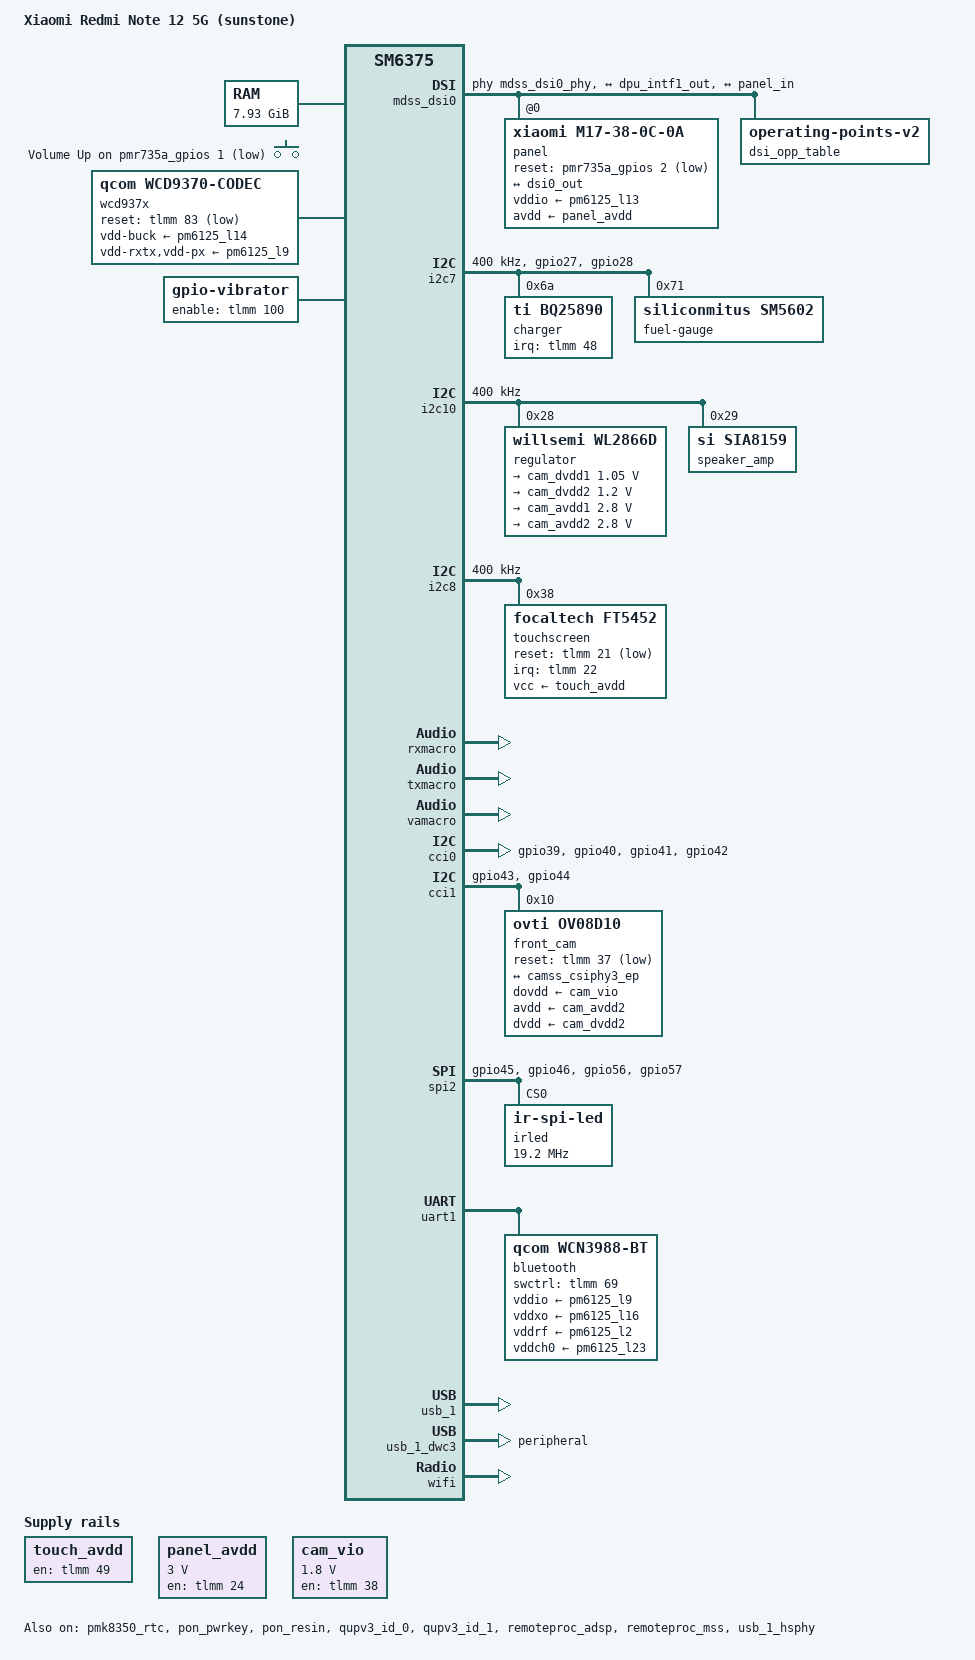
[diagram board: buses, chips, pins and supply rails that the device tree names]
// SPDX-License-Identifier: BSD-3-Clause
/*
 * Xiaomi Redmi Note 12 5G (sunstone), SM4375 "blair".
 *
 * Built on mainline's sm6375.dtsi ("holi", the SoC blair derives from: same CPU, GIC, GCC clock/reset
 * indices and USB block as the downstream blair DT). Board values from the phone's live DT
 * (2026-10-20) and the downstream DT. Until 2026-10-25 this was a chain of one tree per milestone
 * (m1 -> ... -> m6 -> m6d, each including the previous one); git tag dts-milestones has them.
 *
 * - USB: HS PHY on RPM regulators, dwc3 as a peripheral (the NCM gadget carries ssh).
 * - UFS: ufshc@4804000 with one lane and a QMP v4 PHY that downstream drives as
 *   "qcom,ufs-phy-qmp-v4-yupik" (SC7280 tables, kernel/patches/0001 adds the one-lane sm6375
 *   entry). Inline crypto (ICE) is left out. No interconnect driver for sm6375 yet: bus votes stay
 *   as ABL left them.
 * - PMICs as on the downstream DT and Sony's pdx225: PM6125 (SID 0/1), PMK8350 on SID 6, PMR735A.
 *   Keys (downstream gpio-keys and qpnp-power-on): power = PM6125 PON KPDPWR, volume down = PM6125
 *   PON RESIN, volume up = PMR735A GPIO1 (active low) -- the reverse of pdx225's volume keys.
 *   RTC: PMK8350 (read-only for Linux; the offset to real time is kept in userspace).
 * - Touch: FocalTech FT5452 at 0x38 on i2c8 (QUP1 SE2, GPIO19/20). TZ leaves that SE in GSI mode
 *   (FIFO disabled), which i2c-qcom-geni handles through GPI DMA. Reset GPIO21, IRQ GPIO22, AVDD
 *   switched by GPIO49 (downstream focaltech,avdd-gpio); the IO supply stays as ABL set it.
 * - Battery: on i2c7 (QUP1 SE1, GPIO27/28, FIFO mode), the SC8989X charger at 0x6a (BQ25890
 *   register map; IRQ GPIO48, charge enable GPIO53 low) and the SM5602 gauge at 0x71 (local patch
 *   0003).
 * - Modem (MPSS PAS) running the WLAN firmware of the WCN3988 (chip 0x150, WLAN.HL.3.3.2), which
 *   Linux talks to through ath10k snoc. Firmware comes read-only from the phone's modem_a partition
 *   (sunstone-fw-install in rootfs-overlay); rmtfs serves copies of modemst1/2, fsg and fsc, so the
 *   EFS partitions are never written. WLAN supplies as on the downstream icnss node (and Sony's
 *   pdx225): cx-mx PMR735A L2, 1.8 V XO PM6125 L16, 1.3 V RFA PM6125 L2, 3.3 V ch0/ch1 PM6125
 *   L23/L21. MSA at wlan@86500000 and the modem carveout at 0x8b800000 match the dtsi.
 * - GPU: sm6375.dtsi has no GPU nodes. This is mainline's a619_holi (chip id 0x06010901, GMU
 *   wrapper as on sm6115's a610), with values from the downstream kgsl node: registers 0x5900000 /
 *   cx 0x599e000 / dbgc 0x5961000, GMU wrapper 0x596a000, IRQ SPI 177, GX rail = RPM pm6125_s8
 *   levels (rpmpd VDDGX). Speed bins from the qfprom fuse at 0x6015 (downstream gpu_speed_bin):
 *   bins 0 and 190 run up to 900 MHz, 177 up to 840 MHz, 148 (this phone) up to 700 MHz; 650 MHz
 *   and below are common to all. The zap shader is the phone's own a615_zap (vendor partition, not
 *   in this repository).
 * - Display: MDSS/DPU/DSI laid out as mainline's qcom,sm6375-mdss binding example, with the
 *   downstream DT's values: MDSS IRQ SPI 186 (the binding example's 83 is not this SoC's), apps
 *   SMMU stream 0x820, DSC_0, INTF_1 to DSI0 + the 7nm PHY. The panel is the "m17 38 0c 0a"
 *   1080x2400 AMOLED in video mode with DSC 1.1 (kernel/patches/0008): vddio = PM6125 L13 1.86 V,
 *   avdd = 3.0 V switched by GPIO24, reset on PMR735A GPIO2 (active low), TE on GPIO23. DSI: vdda
 *   1.2 V = PM6125 L4, refgen. One msm DRM device drives display and GPU. ABL's splash is described
 *   as a simple-framebuffer, so simpledrm shows the console until msm's KMS takes over.
 * - Cameras: CCI0/CCI1 and CAMSS (TFE530/CSID530 as qcm2290's, CSIPHY 1.2.1; kernel/patches/0018)
 *   with the downstream DT's values. The sensors' cores and analog parts are on a WL2866D (i2c10,
 *   kernel/patches/0017), their I/O on GPIO38. Fitted: OV48B2Q main (cci0, no driver yet), SC202CS
 *   2 MP (cci1 0x36, no driver yet), OV08D10 front (cci1 0x10, CSIPHY3: described below).
 *
 * clk_ignore_unused and pd_ignore_unused (bootargs) keep GCC/RPM from switching off what ABL left
 * running.
 */
/dts-v1/;

#define PMK8350_SID 6

#include <dt-bindings/clock/qcom,sm6375-dispcc.h>
#include <dt-bindings/clock/qcom,sm6375-gpucc.h>
#include <dt-bindings/gpio/gpio.h>
#include <dt-bindings/soc/qcom,apr.h>
#include <dt-bindings/sound/qcom,q6afe.h>
#include <dt-bindings/sound/qcom,q6asm.h>
#include <dt-bindings/thermal/thermal.h>
#include "sm6375.dtsi"
#include "pm6125.dtsi"
#include "pmk8350.dtsi"
#include "pmr735a.dtsi"

/* the PM6125 PON is the one in use (downstream disables PMK8350's), and the labels collide */
/delete-node/ &pmk8350_pon;

/ {
	model = "Xiaomi Redmi Note 12 5G (sunstone)";
	compatible = "xiaomi,sunstone", "qcom,sm4375", "qcom,sm6375";
	chassis-type = "handset";

	aliases {
		/* the GENI UART driver takes its port number from here (Bluetooth; the console is tty0) */
		serial0 = &uart1;
	};

	chosen {
		#address-cells = <2>;
		#size-cells = <2>;
		ranges;
		/*
		 * consoleblank: the text console turns the panel off after 120 s (the phone is a server,
		 * screen off). watchdog.open_timeout: see the watchdog node.
		 */
		bootargs = "console=tty0 ignore_loglevel printk.devkmsg=on panic=20 reboot=warm rdinit=/init clk_ignore_unused pd_ignore_unused consoleblank=120 watchdog.open_timeout=120";

		framebuffer@85200000 {
			compatible = "simple-framebuffer";
			reg = <0x0 0x85200000 0x0 0xc00000>;
			width = <1080>;
			height = <2400>;
			stride = <(1080 * 4)>;
			format = "a8r8g8b8";
			memory-region = <&splash_mem>;
		};
	};

	memory@80000000 {
		reg = <0x0 0x80000000 0x0 0x3bb00000>,
		      <0x0 0xc0000000 0x0 0xc0000000>,
		      <0x1 0x80000000 0x1 0x00000000>;
	};

	reserved-memory {
		splash_mem: splash@85200000 {
			reg = <0x0 0x85200000 0x0 0xc00000>;
			no-map;
		};

		/* the downstream kernel's layout, so either kernel reads the other's records */
		ramoops@d0000000 {
			compatible = "ramoops";
			reg = <0x0 0xd0000000 0x0 0x200000>;
			console-size = <0x100000>;
			pmsg-size = <0x100000>;
		};
	};

	/* the touch controller's analog supply, switched by GPIO49; on already when ABL hands over */
	touch_avdd: touch-avdd-regulator {
		compatible = "regulator-fixed";
		regulator-name = "touch_avdd";
		gpio = <&tlmm 49 GPIO_ACTIVE_HIGH>;
		enable-active-high;
		regulator-boot-on;
		pinctrl-0 = <&ts_avdd_default>;
		pinctrl-names = "default";
	};

	panel_avdd: panel-avdd-regulator {
		compatible = "regulator-fixed";
		regulator-name = "panel_avdd";
		regulator-min-microvolt = <3000000>;
		regulator-max-microvolt = <3000000>;
		gpio = <&tlmm 24 GPIO_ACTIVE_HIGH>;
		enable-active-high;
		startup-delay-us = <233>;
		/* on when ABL hands over: the splash is showing */
		regulator-boot-on;
		pinctrl-0 = <&panel_avdd_default>;
		pinctrl-names = "default";
	};

	/*
	 * the camera modules' 1.8 V I/O supply, switched by GPIO38 (downstream CAM_VIO, shared by all
	 * sensors through cam-res-mgr); their cores and analog parts are on the WL2866D (i2c10)
	 */
	cam_vio: cam-vio-regulator {
		compatible = "regulator-fixed";
		regulator-name = "cam_vio";
		regulator-min-microvolt = <1800000>;
		regulator-max-microvolt = <1800000>;
		gpio = <&tlmm 38 GPIO_ACTIVE_HIGH>;
		enable-active-high;
		startup-delay-us = <1000>;
		pinctrl-0 = <&cam_vio_default>;
		pinctrl-names = "default";
	};

	gpio-keys {
		compatible = "gpio-keys";
		label = "gpio-keys";
		pinctrl-0 = <&vol_up_n>;
		pinctrl-names = "default";

		key-volume-up {
			label = "Volume Up";
			linux,code = <KEY_VOLUMEUP>;
			gpios = <&pmr735a_gpios 1 GPIO_ACTIVE_LOW>;
			debounce-interval = <15>;
			linux,can-disable;
			wakeup-source;
		};
	};

	/*
	 * Vibration motor: an enable on GPIO100. The downstream qcom,qpnp-vibrator-ldo-v2 node has no
	 * register, only the pin states vib_ldo_active (pull-up) and vib_ldo_suspend (pull-down); here
	 * the pin is driven instead.
	 */
	/*
	 * Audio codec: WCD9370 (downstream wcd937x-codec) on the LPASS SoundWire buses, reset on GPIO83,
	 * rxtx/px from PM6125 L9 (1.8 V), the buck from L14, MIC BIAS1/3 1.8 V and 2 2.2 V as downstream;
	 * no micbias supply (downstream leaves it empty). Its RX side has the headphone outputs, the
	 * earpiece (EAR) and AUX, which feeds the SIA8159 speaker amplifier (I2C, i2c10 0x29).
	 */
	wcd937x: codec {
		compatible = "qcom,wcd9370-codec";
		pinctrl-0 = <&wcd_reset_n>;
		pinctrl-names = "default";
		reset-gpios = <&tlmm 83 GPIO_ACTIVE_LOW>;
		vdd-buck-supply = <&pm6125_l14>;
		vdd-rxtx-supply = <&pm6125_l9>;
		vdd-px-supply = <&pm6125_l9>;
		qcom,micbias1-microvolt = <1800000>;
		qcom,micbias2-microvolt = <2200000>;
		qcom,micbias3-microvolt = <1800000>;
		qcom,micbias4-microvolt = <1800000>;
		qcom,mbhc-buttons-vthreshold-microvolt = <75000 150000 237000 500000 500000 500000 500000 500000>;
		qcom,rx-device = <&wcd937x_rx>;
		qcom,tx-device = <&wcd937x_tx>;
		#sound-dai-cells = <1>;
	};

	/*
	 * Sound card: APR frontends through the DSP's routing to RX_CODEC_DMA_RX_0 -> RX macro ->
	 * SoundWire (RX) -> WCD9370 (HPHL/HPHR, AUX -> SIA8159 speaker amplifier), as qrb4210-rb2
	 * (sm4250, the same LPASS) does it.
	 */
	sound {
		compatible = "qcom,qrb4210-rb2-sndcard";
		model = "Xiaomi-Sunstone";
		audio-routing = "IN1_HPHL", "HPHL_OUT",
				"IN2_HPHR", "HPHR_OUT",
				"IN3_AUX", "AUX_OUT",
				"Speaker IN", "AUX",
				/*
				 * microphones (stock mixer paths): AMIC1 the main one (ADC1), AMIC3 the second
				 * (ADC2 INP3), AMIC2 the headset's (ADC2 INP2, MIC BIAS2 at 2.2 V); ADC1 comes
				 * in on the TX SoundWire's port 1, the TX macro's SWR_MIC0, ADC2 on port 2,
				 * SWR_MIC4 (its sm6115 widgets are the downstream ones: TX SWR_INPUTn, SWR_MICn)
				 */
				"AMIC1", "MIC BIAS1",
				"AMIC2", "MIC BIAS2",
				"AMIC3", "MIC BIAS3",
				"TX SWR_INPUT0", "ADC1_OUTPUT",
				"TX SWR_INPUT4", "ADC2_OUTPUT",
				"MM_DL1", "MultiMedia1 Playback",
				"MM_DL2", "MultiMedia2 Playback",
				"MultiMedia3 Capture", "MM_UL3";

		mm1-dai-link {
			link-name = "MultiMedia1";

			cpu {
				sound-dai = <&q6asmdai MSM_FRONTEND_DAI_MULTIMEDIA1>;
			};
		};

		mm2-dai-link {
			link-name = "MultiMedia2";

			cpu {
				sound-dai = <&q6asmdai MSM_FRONTEND_DAI_MULTIMEDIA2>;
			};
		};

		mm3-dai-link {
			link-name = "MultiMedia3";

			cpu {
				sound-dai = <&q6asmdai MSM_FRONTEND_DAI_MULTIMEDIA3>;
			};
		};

		wcd-playback-dai-link {
			link-name = "WCD Playback";

			cpu {
				sound-dai = <&q6afedai RX_CODEC_DMA_RX_0>;
			};

			platform {
				sound-dai = <&q6routing>;
			};

			codec {
				/* the amplifier is on this link only to be switched off before the stream stops */
				sound-dai = <&speaker_amp>, <&wcd937x 0>, <&swr1 0>, <&rxmacro 0>;
			};
		};

		wcd-capture-dai-link {
			link-name = "WCD Capture";

			cpu {
				sound-dai = <&q6afedai TX_CODEC_DMA_TX_3>;
			};

			platform {
				sound-dai = <&q6routing>;
			};

			codec {
				sound-dai = <&wcd937x 1>, <&swr0 0>, <&txmacro 0>;
			};
		};
	};

	vibrator {
		compatible = "gpio-vibrator";
		enable-gpios = <&tlmm 100 GPIO_ACTIVE_HIGH>;
		pinctrl-0 = <&vib_en_default>;
		pinctrl-names = "default";
	};

	soc@0 {
		qfprom: efuse@1b40000 {
			compatible = "qcom,sm6375-qfprom", "qcom,qfprom";
			reg = <0x0 0x01b40000 0x0 0x7000>;
			read-only;
			#address-cells = <1>;
			#size-cells = <1>;

			gpu_speed_bin: gpu-speed-bin@6015 {
				reg = <0x6015 0x1>;
				bits = <0 8>;
			};
		};

		ufs_mem_hc: ufshc@4804000 {
			compatible = "qcom,sm6375-ufshc", "qcom,ufshc", "jedec,ufs-2.0";
			reg = <0x0 0x04804000 0x0 0x3000>;
			reg-names = "std";
			interrupts = <GIC_SPI 356 IRQ_TYPE_LEVEL_HIGH>;
			phys = <&ufs_mem_phy>;
			phy-names = "ufsphy";
			lanes-per-direction = <1>;
			#reset-cells = <1>;
			resets = <&gcc GCC_UFS_PHY_BCR>;
			reset-names = "rst";
			reset-gpios = <&tlmm 156 GPIO_ACTIVE_LOW>;

			power-domains = <&gcc UFS_PHY_GDSC>;
			iommus = <&apps_smmu 0x60 0x0>;

			clocks = <&gcc GCC_UFS_PHY_AXI_CLK>,
				 <&gcc GCC_SYS_NOC_UFS_PHY_AXI_CLK>,
				 <&gcc GCC_UFS_PHY_AHB_CLK>,
				 <&gcc GCC_UFS_PHY_UNIPRO_CORE_CLK>,
				 <&rpmcc RPM_SMD_XO_CLK_SRC>,
				 <&gcc GCC_UFS_PHY_TX_SYMBOL_0_CLK>,
				 <&gcc GCC_UFS_PHY_RX_SYMBOL_0_CLK>;
			clock-names = "core_clk",
				      "bus_aggr_clk",
				      "iface_clk",
				      "core_clk_unipro",
				      "ref_clk",
				      "tx_lane0_sync_clk",
				      "rx_lane0_sync_clk";
			freq-table-hz = <50000000 200000000>,
					<0 0>,
					<0 0>,
					<37500000 150000000>,
					<0 0>,
					<0 0>,
					<0 0>;

			/* vcc PM6125 L24 (2.95 V), vccq2 PM6125 L11 (1.8 V), vdd-hba = the UFS_PHY GDSC */
			vcc-supply = <&pm6125_l24>;
			vcc-max-microamp = <800000>;
			vccq2-supply = <&pm6125_l11>;
			vccq2-max-microamp = <800000>;
		};

		ufs_mem_phy: phy@4807000 {
			compatible = "qcom,sm6375-qmp-ufs-phy";
			reg = <0x0 0x04807000 0x0 0x1000>;

			clocks = <&rpmcc RPM_SMD_XO_CLK_SRC>,
				 <&gcc GCC_UFS_PHY_PHY_AUX_CLK>,
				 <&gcc GCC_UFS_MEM_CLKREF_CLK>;
			clock-names = "ref",
				      "ref_aux",
				      "qref";

			power-domains = <&gcc UFS_PHY_GDSC>;

			resets = <&ufs_mem_hc 0>;
			reset-names = "ufsphy";

			vdda-phy-supply = <&pm6125_l7>;
			vdda-pll-supply = <&pm6125_l4>;

			#phy-cells = <0>;
		};

		/*
		 * IPA (the modem's data path): the downstream node is qcom,ipa-hw-ver 0x14 = IPA v4.11, as on
		 * sc7280, so mainline's v4.11 data. Downstream: ipa-base 0x5800000 (the IPA registers at
		 * +0x40000, the shared memory at +0x50000 as on sc7280's 0x1e00000 block), gsi-base 0x5804000,
		 * IRQ SPI 257 / 259 level, SMMU streams 0x4a0 (AP) and 0x4a2 (uC), core clock = RPM IPA clock,
		 * the GSI firmware ipa_fws (PAS 15) loaded by Linux into the ipa-fw carve-out, the modem's
		 * tables in IMEM at 0xc123000 (downstream qcom,additional-mapping). The shared memory is 0x3000
		 * bytes (SHARED_MEM_SIZE; sc7280's 0x4ad0 gets "limiting IPA memory size"). No interconnect driver for
		 * sm6375: no bus votes (the ipa driver skips paths that are not described).
		 */
		ipa: ipa@5840000 {
			compatible = "qcom,sc7280-ipa";

			iommus = <&apps_smmu 0x4a0 0x0>,
				 <&apps_smmu 0x4a2 0x0>;
			reg = <0x0 0x05840000 0x0 0x8000>,
			      <0x0 0x05850000 0x0 0x3000>,
			      <0x0 0x05804000 0x0 0x23000>;
			reg-names = "ipa-reg",
				    "ipa-shared",
				    "gsi";

			interrupts-extended = <&intc GIC_SPI 257 IRQ_TYPE_LEVEL_HIGH>,
					      <&intc GIC_SPI 259 IRQ_TYPE_LEVEL_HIGH>,
					      <&ipa_smp2p_in 0 IRQ_TYPE_EDGE_RISING>,
					      <&ipa_smp2p_in 1 IRQ_TYPE_EDGE_RISING>;
			interrupt-names = "ipa",
					  "gsi",
					  "ipa-clock-query",
					  "ipa-setup-ready";

			clocks = <&rpmcc RPM_SMD_IPA_CLK>;
			clock-names = "core";

			qcom,smem-states = <&ipa_smp2p_out 0>,
					   <&ipa_smp2p_out 1>;
			qcom,smem-state-names = "ipa-clock-enabled-valid",
						"ipa-clock-enabled";

			qcom,gsi-loader = "self";
			memory-region = <&pil_ipa_fw_mem>;
			firmware-name = "qcom/sm4375/xiaomi/sunstone/ipa_fws.mdt";

			sram = <&ipa_modem_tables>;
		};

		/* IMEM slice for the modem's IPA tables (sm6375.dtsi's imem node starts at 0xc125000) */
		ipa_modem_tables: sram@c123000 {
			reg = <0x0 0x0c123000 0x0 0x2000>;
		};

		gpu: gpu@5900000 {
			compatible = "qcom,adreno-619.1", "qcom,adreno";
			reg = <0x0 0x05900000 0x0 0x40000>,
			      <0x0 0x0599e000 0x0 0x1000>,
			      <0x0 0x05961000 0x0 0x800>;
			reg-names = "kgsl_3d0_reg_memory",
				    "cx_mem",
				    "cx_dbgc";

			/* no (real) GMU: the GPU driver handles the clocks itself */
			clocks = <&gpucc GPU_CC_GX_GFX3D_CLK>,
				 <&gpucc GPU_CC_AHB_CLK>,
				 <&gcc GCC_BIMC_GPU_AXI_CLK>,
				 <&gcc GCC_GPU_MEMNOC_GFX_CLK>,
				 <&gpucc GPU_CC_CX_GMU_CLK>,
				 <&gpucc GPU_CC_CXO_CLK>;
			clock-names = "core",
				      "iface",
				      "mem_iface",
				      "alt_mem_iface",
				      "gmu",
				      "xo";

			interrupts = <GIC_SPI 177 IRQ_TYPE_LEVEL_HIGH>;

			iommus = <&adreno_smmu 0>;
			operating-points-v2 = <&gpu_opp_table>;
			power-domains = <&rpmpd SM6375_VDDGX>;
			qcom,gmu = <&gmu_wrapper>;

			nvmem-cells = <&gpu_speed_bin>;
			nvmem-cell-names = "speed_bin";
			#cooling-cells = <2>;

			gpu_zap_shader: zap-shader {
				memory-region = <&pil_gpu_micro_code_mem>;
				firmware-name = "qcom/sm4375/xiaomi/sunstone/a615_zap.mdt";
			};

			/*
			 * opp-supported-hw: BIT(n) for the catalog's speed bins {0: 0, 190: 1, 177: 2, 148: 3}
			 * (148 from kernel/patches/0007; sunstone is a bin-148 part, downstream max 700 MHz,
			 * which gpucc cannot make: 650 MHz is its top here)
			 */
			gpu_opp_table: opp-table {
				compatible = "operating-points-v2";

				opp-900000000 {
					opp-hz = /bits/ 64 <900000000>;
					required-opps = <&rpmpd_opp_turbo_no_cpr>;
					opp-supported-hw = <0x3>;
				};

				opp-840000000 {
					opp-hz = /bits/ 64 <840000000>;
					required-opps = <&rpmpd_opp_turbo>;
					opp-supported-hw = <0x7>;
				};

				opp-770000000 {
					opp-hz = /bits/ 64 <770000000>;
					required-opps = <&rpmpd_opp_nom_plus>;
					opp-supported-hw = <0x7>;
				};

				opp-650000000 {
					opp-hz = /bits/ 64 <650000000>;
					required-opps = <&rpmpd_opp_nom>;
					opp-supported-hw = <0xf>;
				};

				opp-490000000 {
					opp-hz = /bits/ 64 <490000000>;
					required-opps = <&rpmpd_opp_svs_plus>;
					opp-supported-hw = <0xf>;
				};

				opp-390000000 {
					opp-hz = /bits/ 64 <390000000>;
					required-opps = <&rpmpd_opp_svs>;
					opp-supported-hw = <0xf>;
				};

				opp-266000000 {
					opp-hz = /bits/ 64 <266000000>;
					required-opps = <&rpmpd_opp_low_svs>;
					opp-supported-hw = <0xf>;
				};
			};
		};

		gmu_wrapper: gmu@596a000 {
			compatible = "qcom,adreno-gmu-wrapper";
			reg = <0x0 0x0596a000 0x0 0x30000>;
			reg-names = "gmu";
			power-domains = <&gpucc GPU_CX_GDSC>,
					<&gpucc GPU_GX_GDSC>;
			power-domain-names = "cx", "gx";
		};

		gpucc: clock-controller@5990000 {
			compatible = "qcom,sm6375-gpucc";
			reg = <0x0 0x05990000 0x0 0x9000>;
			clocks = <&rpmcc RPM_SMD_XO_CLK_SRC>,
				 <&gcc GCC_GPU_GPLL0_CLK_SRC>,
				 <&gcc GCC_GPU_GPLL0_DIV_CLK_SRC>,
				 <&gcc GCC_GPU_SNOC_DVM_GFX_CLK>;
			power-domains = <&rpmpd SM6375_VDDGX>;
			required-opps = <&rpmpd_opp_low_svs>;
			#clock-cells = <1>;
			#reset-cells = <1>;
			#power-domain-cells = <1>;
		};

		/*
		 * APSS watchdog, as the downstream qcom,msm-watchdog (0xf410000, bark interrupt SPI 0). Same
		 * register layout as the KPSS watchdog; the sm6115 node is the model, including the edge
		 * trigger (level-high, as downstream, storms for the second between bark and bite).
		 * A bite resets into Linux again (boot-93: 67 s); systemd pets it (RuntimeWatchdogSec).
		 * The shim starts it before Linux; the watchdog core pets it until systemd opens it, for at
		 * most watchdog.open_timeout (bootargs), so a hang during kernel init is reset as well.
		 */
		watchdog@f410000 {
			compatible = "qcom,apss-wdt-sm6375", "qcom,kpss-wdt";
			reg = <0x0 0x0f410000 0x0 0x1000>;
			clocks = <&sleep_clk>;
			interrupts = <GIC_SPI 0 IRQ_TYPE_EDGE_RISING>;
		};

		dispcc: clock-controller@5f00000 {
			compatible = "qcom,sm6375-dispcc";
			reg = <0x0 0x05f00000 0x0 0x20000>;
			clocks = <&rpmcc RPM_SMD_XO_CLK_SRC>,
				 <&gcc GCC_DISP_GPLL0_CLK_SRC>,
				 <&mdss_dsi0_phy 0>,
				 <&mdss_dsi0_phy 1>;
			#clock-cells = <1>;
			#reset-cells = <1>;
			#power-domain-cells = <1>;
		};

		mdss: display-subsystem@5e00000 {
			compatible = "qcom,sm6375-mdss";
			reg = <0x0 0x05e00000 0x0 0x1000>;
			reg-names = "mdss";

			power-domains = <&dispcc MDSS_GDSC>;
			/*
			 * msm resets MDSS at probe: this stops ABL's splash scanout. Without it the DPU still
			 * fetches the splash (0x85200000) when msm switches the display stream to its own
			 * SMMU domain; if MDSS has not been power-collapsed in between (the first modeset
			 * inside the panel's probe holds its parents active) that ends in SMMU faults, DSI
			 * FIFO underflow and a hard hang (LOG.md boot-34-69).
			 */
			resets = <&dispcc DISP_CC_MDSS_CORE_BCR>;

			clocks = <&gcc GCC_DISP_AHB_CLK>,
				 <&dispcc DISP_CC_MDSS_AHB_CLK>,
				 <&dispcc DISP_CC_MDSS_MDP_CLK>;
			clock-names = "iface", "ahb", "core";

			interrupts = <GIC_SPI 186 IRQ_TYPE_LEVEL_HIGH>;
			interrupt-controller;
			#interrupt-cells = <1>;

			iommus = <&apps_smmu 0x820 0x2>;
			#address-cells = <2>;
			#size-cells = <2>;
			ranges;

			mdp: display-controller@5e01000 {
				compatible = "qcom,sm6375-dpu";
				reg = <0x0 0x05e01000 0x0 0x8e030>,
				      <0x0 0x05eb0000 0x0 0x2008>;
				reg-names = "mdp", "vbif";

				clocks = <&gcc GCC_DISP_HF_AXI_CLK>,
					 <&dispcc DISP_CC_MDSS_AHB_CLK>,
					 <&dispcc DISP_CC_MDSS_ROT_CLK>,
					 <&dispcc DISP_CC_MDSS_MDP_LUT_CLK>,
					 <&dispcc DISP_CC_MDSS_MDP_CLK>,
					 <&dispcc DISP_CC_MDSS_VSYNC_CLK>,
					 <&gcc GCC_DISP_THROTTLE_CORE_CLK>;
				clock-names = "bus", "iface", "rot", "lut", "core", "vsync", "throttle";

				assigned-clocks = <&dispcc DISP_CC_MDSS_VSYNC_CLK>;
				assigned-clock-rates = <19200000>;

				operating-points-v2 = <&mdp_opp_table>;
				power-domains = <&rpmpd SM6375_VDDCX>;

				interrupt-parent = <&mdss>;
				interrupts = <0>;

				ports {
					#address-cells = <1>;
					#size-cells = <0>;

					port@0 {
						reg = <0>;
						dpu_intf1_out: endpoint {
							remote-endpoint = <&dsi0_in>;
						};
					};
				};

				/* dispcc MDP rates; 1080x2400@120 needs ~400 MHz */
				mdp_opp_table: opp-table {
					compatible = "operating-points-v2";

					opp-19200000 {
						opp-hz = /bits/ 64 <19200000>;
						required-opps = <&rpmpd_opp_min_svs>;
					};

					opp-200000000 {
						opp-hz = /bits/ 64 <200000000>;
						required-opps = <&rpmpd_opp_low_svs>;
					};

					opp-300000000 {
						opp-hz = /bits/ 64 <300000000>;
						required-opps = <&rpmpd_opp_svs>;
					};

					opp-373500000 {
						opp-hz = /bits/ 64 <373500000>;
						required-opps = <&rpmpd_opp_svs_plus>;
					};

					opp-470000000 {
						opp-hz = /bits/ 64 <470000000>;
						required-opps = <&rpmpd_opp_nom>;
					};

					opp-560000000 {
						opp-hz = /bits/ 64 <560000000>;
						required-opps = <&rpmpd_opp_turbo>;
					};
				};
			};

			mdss_dsi0: dsi@5e94000 {
				compatible = "qcom,sm6375-dsi-ctrl", "qcom,mdss-dsi-ctrl";
				reg = <0x0 0x05e94000 0x0 0x400>;
				reg-names = "dsi_ctrl";

				interrupt-parent = <&mdss>;
				interrupts = <4>;

				clocks = <&dispcc DISP_CC_MDSS_BYTE0_CLK>,
					 <&dispcc DISP_CC_MDSS_BYTE0_INTF_CLK>,
					 <&dispcc DISP_CC_MDSS_PCLK0_CLK>,
					 <&dispcc DISP_CC_MDSS_ESC0_CLK>,
					 <&dispcc DISP_CC_MDSS_AHB_CLK>,
					 <&gcc GCC_DISP_HF_AXI_CLK>;
				clock-names = "byte", "byte_intf", "pixel", "core", "iface", "bus";

				assigned-clocks = <&dispcc DISP_CC_MDSS_BYTE0_CLK_SRC>,
						  <&dispcc DISP_CC_MDSS_PCLK0_CLK_SRC>;
				assigned-clock-parents = <&mdss_dsi0_phy 0>, <&mdss_dsi0_phy 1>;

				operating-points-v2 = <&dsi_opp_table>;
				power-domains = <&rpmpd SM6375_VDDMX>;

				vdda-supply = <&pm6125_l4>;
				refgen-supply = <&refgen>;

				phys = <&mdss_dsi0_phy>;
				phy-names = "dsi";

				#address-cells = <1>;
				#size-cells = <0>;

				panel@0 {
					compatible = "xiaomi,m17-38-0c-0a";
					reg = <0>;

					vddio-supply = <&pm6125_l13>;
					avdd-supply = <&panel_avdd>;
					reset-gpios = <&pmr735a_gpios 2 GPIO_ACTIVE_LOW>;

					pinctrl-0 = <&panel_reset_default &mdp_vsync_default>;
					pinctrl-names = "default";

					port {
						panel_in: endpoint {
							remote-endpoint = <&dsi0_out>;
						};
					};
				};

				ports {
					#address-cells = <1>;
					#size-cells = <0>;

					port@0 {
						reg = <0>;
						dsi0_in: endpoint {
							remote-endpoint = <&dpu_intf1_out>;
						};
					};

					port@1 {
						reg = <1>;
						dsi0_out: endpoint {
							remote-endpoint = <&panel_in>;
							data-lanes = <0 1 2 3>;
						};
					};
				};

				dsi_opp_table: opp-table {
					compatible = "operating-points-v2";

					opp-187500000 {
						opp-hz = /bits/ 64 <187500000>;
						required-opps = <&rpmpd_opp_low_svs>;
					};

					opp-300000000 {
						opp-hz = /bits/ 64 <300000000>;
						required-opps = <&rpmpd_opp_svs>;
					};

					opp-358000000 {
						opp-hz = /bits/ 64 <358000000>;
						required-opps = <&rpmpd_opp_svs_plus>;
					};
				};
			};

			mdss_dsi0_phy: phy@5e94400 {
				compatible = "qcom,sm6375-dsi-phy-7nm";
				reg = <0x0 0x05e94400 0x0 0x200>,
				      <0x0 0x05e94600 0x0 0x280>,
				      <0x0 0x05e94900 0x0 0x264>;
				reg-names = "dsi_phy", "dsi_phy_lane", "dsi_pll";

				#clock-cells = <1>;
				#phy-cells = <0>;

				clocks = <&dispcc DISP_CC_MDSS_AHB_CLK>,
					 <&rpmcc RPM_SMD_XO_CLK_SRC>;
				clock-names = "iface", "ref";
			};
		};
	};
};

/* blair's firmware carve-outs sit higher than holi's from adsp on (live DT) */
&pil_adsp_mem { reg = <0x0 0x86700000 0x0 0x2800000>; };
&pil_cdsp_mem { reg = <0x0 0x88f00000 0x0 0x1e00000>; };
&pil_video_mem { reg = <0x0 0x8ad00000 0x0 0x500000>; };
&pil_ipa_fw_mem { reg = <0x0 0x8b200000 0x0 0x10000>; };
&pil_ipa_gsi_mem { reg = <0x0 0x8b210000 0x0 0xa000>; };
&pil_gpu_micro_code_mem { reg = <0x0 0x8b21a000 0x0 0x2000>; };

/*
 * sm6375.dtsi leaves "qcom,adreno-smmu" out of the GPU SMMU: without it arm-smmu-qcom does not use
 * its Adreno implementation and msm gets no per-process page tables ("No per-process page tables").
 */
&adreno_smmu {
	compatible = "qcom,sm6375-smmu-v2", "qcom,adreno-smmu", "qcom,smmu-v2";
};

/* blair's gold cluster tops out at 2016 MHz (EPSS LUT), a step holi's table does not have */
&cpu6_opp_table {
	opp-2016000000 {
		opp-hz = /bits/ 64 <2016000000>;
		opp-peak-kBps = <(1497600 * 32)>;
	};
};

&gpi_dma0 {
	status = "okay";
};

&gpi_dma1 {
	status = "okay";
};

&i2c7 {
	clock-frequency = <400000>;
	pinctrl-0 = <&qup_i2c7_default>;
	pinctrl-names = "default";
	status = "okay";

	/*
	 * Taken over without a reset. Linux programs the charging settings instead of reading back
	 * what the bootloader left (that capped ICHG at 512 mA), below the downstream 3 A: 2 A (about
	 * 1.86 A on the SC89890H, whose ICHG step is smaller), precharge/termination as read back on
	 * boot-13. Input current stays with the chip's own BC1.2 detection; JEITA via the TS pin in
	 * hardware. CV 4.1 V (4.096 V in 16 mV steps, about 80 %) rather than the downstream 4.45 V: the
	 * phone lives on its charger as a server and the battery is its UPS; 24/7 at 4.45 V ages it
	 * fast. For a full charge:
	 * echo 4450000 > /sys/class/power_supply/bq25890-charger-0/constant_charge_voltage
	 */
	charger: charger@6a {
		compatible = "ti,bq25890";
		reg = <0x6a>;
		interrupts-extended = <&tlmm 48 IRQ_TYPE_EDGE_FALLING>;
		pinctrl-0 = <&chg_int_default &chg_en_default>;
		pinctrl-names = "default";

		linux,skip-reset;
		ti,battery-regulation-voltage = <4100000>;
		ti,charge-current = <2000000>;
		ti,termination-current = <256000>;
		ti,precharge-current = <192000>;
		ti,minimum-sys-voltage = <3600000>;
		ti,boost-voltage = <5000000>;
		ti,boost-max-current = <1650000>;
		ti,thermal-regulation-threshold = <120>;
	};

	fuel-gauge@71 {
		compatible = "siliconmitus,sm5602";
		reg = <0x71>;
		power-supplies = <&charger>;
		/* battery NTC reading for -20..80 C (downstream battery0,thermal_table) */
		siliconmitus,thermal-table = <
			0x3b3a 0x3516 0x2f05 0x28f4 0x2323 0x1d80 0x1804 0x12e1 0xda7 0x8b3
			0x3d6 0xf6f2 0xf273 0xee03 0xe9d0 0xe5c7 0xe1e2 0xde2c 0xda98 0xd727
			0xd3d8 0xd0b2 0xcdac 0xcac8 0xc806 0xc55c 0xc2d0 0xc069 0xbe17 0xbbe1
			0xb9c6 0xb7c0 0xb5d3 0xb400 0xb242 0xb092 0xaefd 0xad7c 0xac06 0xaaa6
			0xa953 0xa814 0xa6de 0xa5be 0xa4a5 0xa39c 0xa2a1 0xa1b1 0xa0cb 0x9ff3
			0x9f23 0x9e59 0x9d9a 0x9ce7 0x9c3b 0x9b95 0x9af7 0x9a62 0x99d2 0x994b
			0x98cb 0x984e 0x97d6 0x9765 0x96fa 0x9693 0x9631 0x95d3 0x9579 0x9523
			0x94cf 0x9481 0x9435 0x93ec 0x93a6 0x9364 0x9325 0x92ea 0x92b1 0x927b
			0x9245 0x9212 0x91e1 0x91b2 0x9185 0x915a 0x9132 0x910b 0x90e6 0x90c2
			0x90a0 0x907e 0x905e 0x9040 0x9022 0x9006 0x8fea 0x8fd0 0x8fb7 0x8fa0
			0x8f8a>;
	};
};

&i2c10 {
	clock-frequency = <400000>;
	status = "okay";

	/*
	 * Speaker amplifier (downstream sipa_i2c / si_pa.0, sia8159, si_pa_disable_pin: no enable GPIO,
	 * switched over I2C only); its input is the WCD9370's AUX output. Local patch 0012.
	 */
	/*
	 * the camera LDOs (downstream xiaomi,wl2866d; VIN1 = PM6125 S6 1.35 V, on as ABL leaves it).
	 * Voltages as the vendor driver sets them; which sensor uses which, found by switching them
	 * one at a time: the main sensor LDO1 + LDO3, the 8 MP one LDO2 + LDO4, the 2 MP one LDO4.
	 */
	regulator@28 {
		compatible = "willsemi,wl2866d";
		reg = <0x28>;

		regulators {
			cam_dvdd1: ldo1 {
				regulator-name = "cam_dvdd1";
				regulator-min-microvolt = <1050000>;
				regulator-max-microvolt = <1050000>;
				regulator-active-discharge = <1>;
			};

			cam_dvdd2: ldo2 {
				regulator-name = "cam_dvdd2";
				regulator-min-microvolt = <1200000>;
				regulator-max-microvolt = <1200000>;
				regulator-active-discharge = <1>;
			};

			cam_avdd1: ldo3 {
				regulator-name = "cam_avdd1";
				regulator-min-microvolt = <2800000>;
				regulator-max-microvolt = <2800000>;
				regulator-active-discharge = <1>;
			};

			cam_avdd2: ldo4 {
				regulator-name = "cam_avdd2";
				regulator-min-microvolt = <2800000>;
				regulator-max-microvolt = <2800000>;
				regulator-active-discharge = <1>;
			};
		};
	};

	speaker_amp: amplifier@29 {
		compatible = "si,sia8159";
		reg = <0x29>;
		sound-name-prefix = "Speaker";
		#sound-dai-cells = <0>;
	};
};

&i2c8 {
	clock-frequency = <400000>;
	status = "okay";

	touchscreen@38 {
		compatible = "focaltech,ft5452";
		reg = <0x38>;
		interrupts-extended = <&tlmm 22 IRQ_TYPE_EDGE_FALLING>;
		reset-gpios = <&tlmm 21 GPIO_ACTIVE_LOW>;
		vcc-supply = <&touch_avdd>;
		/* the IC reports 1.25x panel pixels (boot-11 target taps: 0.805 px per unit, both axes) */
		touchscreen-size-x = <1350>;
		touchscreen-size-y = <3000>;
		pinctrl-0 = <&ts_int_default &ts_reset_default>;
		pinctrl-names = "default";
	};
};

/* not used on this board: the PM6125 RTC is disabled in hardware (probe gets -EPERM) */
&pm6125_rtc {
	status = "disabled";
};

/*
 * A normal `reboot` writes PON reason 0 and comes back into Linux; `reboot bootloader`
 * (`systemctl reboot --reboot-argument=bootloader`, mode-bootloader in pm6125.dtsi) goes to fastboot.
 * A panic (emergency restart, no reboot notifiers) leaves the reason as it was: since 2026-10-23 the
 * shim no longer sets "bootloader" before Linux (unless built with PON_FASTBOOT=1), so it reboots
 * into Linux too.
 */
&pm6125_pon {
	mode-normal = <0x0>;
};

&pmk8350_rtc {
	status = "okay";
};

/* the PMK8350 ADC has no channels described yet */
&pmk8350_vadc {
	status = "disabled";
};

&pmr735a_gpios {
	vol_up_n: vol-up-n-state {
		pins = "gpio1";
		function = "normal";
		power-source = <1>;
		bias-pull-up;
		input-enable;
	};

	panel_reset_default: panel-reset-default-state {
		pins = "gpio2";
		function = "normal";
		power-source = <1>;
		bias-disable;
		output-high;
	};
};

&pon_pwrkey {
	status = "okay";
};

&pon_resin {
	linux,code = <KEY_VOLUMEDOWN>;
	status = "okay";
};

&qupv3_id_0 {
	status = "okay";
};

&qupv3_id_1 {
	status = "okay";
};

/*
 * LPASS digital codec blocks: holi's LPASS (bolero 2.x) is sm6115's, at the same addresses and with
 * the same LPI pin functions, laid out as Linaro's sm6115 LPASS patches (qrb4210-rb2 audio series,
 * 2024-12): RX/TX/VA macros clocked by the DSP (q6afe clocks), the RX SoundWire (WCD RX side) and
 * the VA/TX SoundWire (WCD TX side, VA swr IRQ = MPM pin 5 = SPI 296), their CGCR resets. Port
 * parameters are sm6115's for the same WCD937x.
 */
&soc {
	rxmacro: codec@a600000 {
		compatible = "qcom,sm6115-lpass-rx-macro";
		reg = <0x0 0x0a600000 0x0 0x1000>;

		clocks = <&q6afecc LPASS_CLK_ID_RX_CORE_MCLK LPASS_CLK_ATTRIBUTE_COUPLE_NO>,
			 <&q6afecc LPASS_CLK_ID_RX_CORE_NPL_MCLK LPASS_CLK_ATTRIBUTE_COUPLE_NO>,
			 <&q6afecc LPASS_HW_DCODEC_VOTE LPASS_CLK_ATTRIBUTE_COUPLE_NO>,
			 <&vamacro>;
		clock-names = "mclk",
			      "npl",
			      "dcodec",
			      "fsgen";
		assigned-clocks = <&q6afecc LPASS_CLK_ID_RX_CORE_MCLK LPASS_CLK_ATTRIBUTE_COUPLE_NO>,
				  <&q6afecc LPASS_CLK_ID_RX_CORE_NPL_MCLK LPASS_CLK_ATTRIBUTE_COUPLE_NO>;
		assigned-clock-rates = <22579200>,
				       <22579200>;
		#clock-cells = <0>;
		clock-output-names = "mclk";
		#sound-dai-cells = <1>;
	};

	swr1: soundwire@a610000 {
		compatible = "qcom,soundwire-v1.6.0";
		reg = <0x0 0x0a610000 0x0 0x2000>;
		/*
		 * rising edge, as the driver requests it: with LEVEL_HIGH here the mapping no longer
		 * matches after the first request, and the controller cannot probe again (after an
		 * ADSP restart unbinds it): "irq: type mismatch, failed to map hwirq-329"
		 */
		interrupts = <GIC_SPI 297 IRQ_TYPE_EDGE_RISING>;

		clocks = <&rxmacro>;
		clock-names = "iface";

		resets = <&lpass_audiocc 0>;
		reset-names = "swr_audio_cgcr";

		pinctrl-0 = <&lpass_rx_swr_active>;
		pinctrl-names = "default";

		label = "RX";
		qcom,din-ports = <0>;
		qcom,dout-ports = <5>;

		qcom,ports-sinterval-low = /bits/ 8 <0x03 0x1f 0x1f 0x07 0x00>;
		qcom,ports-offset1 = /bits/ 8 <0x00 0x00 0x0b 0x01 0x00>;
		qcom,ports-offset2 = /bits/ 8 <0x00 0x00 0x0b 0x00 0x00>;
		qcom,ports-hstart = /bits/ 8 <0xff 0x03 0xff 0xff 0xff>;
		qcom,ports-hstop = /bits/ 8 <0xff 0x06 0xff 0xff 0xff>;
		qcom,ports-word-length = /bits/ 8 <0x01 0x07 0x04 0xff 0xff>;
		qcom,ports-block-pack-mode = /bits/ 8 <0xff 0x00 0x01 0xff 0xff>;
		qcom,ports-block-group-count = /bits/ 8 <0xff 0xff 0xff 0xff 0x00>;
		qcom,ports-lane-control = /bits/ 8 <0x01 0x00 0x00 0x00 0x00>;

		#sound-dai-cells = <1>;
		#address-cells = <2>;
		#size-cells = <0>;

		wcd937x_rx: codec@0,4 {
			compatible = "sdw20217010a00";
			reg = <0 4>;
			qcom,rx-port-mapping = <1 2 3 4 5>;
		};
	};

	txmacro: codec@a620000 {
		compatible = "qcom,sm6115-lpass-tx-macro";
		reg = <0x0 0x0a620000 0x0 0x1000>;

		clocks = <&q6afecc LPASS_CLK_ID_TX_CORE_MCLK LPASS_CLK_ATTRIBUTE_COUPLE_NO>,
			 <&q6afecc LPASS_CLK_ID_TX_CORE_NPL_MCLK LPASS_CLK_ATTRIBUTE_COUPLE_NO>,
			 <&q6afecc LPASS_HW_DCODEC_VOTE LPASS_CLK_ATTRIBUTE_COUPLE_NO>,
			 <&vamacro>;
		clock-names = "mclk",
			      "npl",
			      "dcodec",
			      "fsgen";
		assigned-clocks = <&q6afecc LPASS_CLK_ID_TX_CORE_MCLK LPASS_CLK_ATTRIBUTE_COUPLE_NO>,
				  <&q6afecc LPASS_CLK_ID_TX_CORE_NPL_MCLK LPASS_CLK_ATTRIBUTE_COUPLE_NO>;
		assigned-clock-rates = <19200000>,
				       <19200000>;
		#clock-cells = <0>;
		clock-output-names = "mclk";
		#sound-dai-cells = <1>;
	};

	lpass_audiocc: clock-controller@a6a9000 {
		compatible = "qcom,sm6115-lpassaudiocc";
		reg = <0x0 0x0a6a9000 0x0 0x1000>;
		#reset-cells = <1>;
	};

	vamacro: codec@a730000 {
		compatible = "qcom,sm6115-lpass-va-macro";
		reg = <0x0 0x0a730000 0x0 0x1000>;
		clocks = <&q6afecc LPASS_CLK_ID_TX_CORE_MCLK LPASS_CLK_ATTRIBUTE_COUPLE_NO>,
			 <&q6afecc LPASS_HW_DCODEC_VOTE LPASS_CLK_ATTRIBUTE_COUPLE_NO>,
			 <&q6afecc LPASS_CLK_ID_TX_CORE_NPL_MCLK LPASS_CLK_ATTRIBUTE_COUPLE_NO>;
		clock-names = "mclk",
			      "dcodec",
			      "npl";
		assigned-clocks = <&q6afecc LPASS_CLK_ID_TX_CORE_MCLK LPASS_CLK_ATTRIBUTE_COUPLE_NO>,
				  <&q6afecc LPASS_CLK_ID_TX_CORE_NPL_MCLK LPASS_CLK_ATTRIBUTE_COUPLE_NO>;
		assigned-clock-rates = <19200000>,
				       <19200000>;
		#clock-cells = <0>;
		clock-output-names = "fsgen";
		#sound-dai-cells = <1>;
	};

	swr0: soundwire@a740000 {
		compatible = "qcom,soundwire-v1.6.0";
		reg = <0x0 0x0a740000 0x0 0x2000>;
		/*
		 * wakeup: the stock swr_wake_irq. The controller clock-stops when idle, and the WCD's
		 * alerts (the headset jack's MBHC) only get through it once the bus is woken up.
		 */
		/* the core interrupt rising edge, as for swr1 */
		interrupts-extended = <&intc GIC_SPI 296 IRQ_TYPE_EDGE_RISING>,
				      <&tlmm 128 IRQ_TYPE_LEVEL_HIGH>;
		interrupt-names = "core", "wakeup";
		clocks = <&txmacro>;
		clock-names = "iface";

		resets = <&lpasscc 0>;
		reset-names = "swr_audio_cgcr";

		pinctrl-0 = <&lpass_tx_swr_active>;
		pinctrl-names = "default";

		label = "VA_TX";
		qcom,din-ports = <3>;
		qcom,dout-ports = <0>;

		qcom,ports-sinterval-low = /bits/ 8 <0x03 0x03 0x03>;
		qcom,ports-offset1 = /bits/ 8 <0x01 0x02 0x01>;
		qcom,ports-offset2 = /bits/ 8 <0x00 0x00 0x00>;
		qcom,ports-hstart = /bits/ 8 <0xff 0xff 0xff>;
		qcom,ports-hstop = /bits/ 8 <0xff 0xff 0xff>;
		qcom,ports-word-length = /bits/ 8 <0xff 0xff 0xff>;
		qcom,ports-block-pack-mode = /bits/ 8 <0xff 0xff 0xff>;
		qcom,ports-block-group-count = /bits/ 8 <0xff 0xff 0xff>;
		qcom,ports-lane-control = /bits/ 8 <0x00 0x00 0x00>;

		#sound-dai-cells = <1>;
		#address-cells = <2>;
		#size-cells = <0>;

		wcd937x_tx: codec@0,3 {
			compatible = "sdw20217010a00";
			reg = <0 3>;
			/*
			 * WCD TX ports 1 (ADC1) -> master port 1, 2 (ADC2/3) -> 2, 3 (DMIC0-3, MBHC) and 4
			 * (DMIC4-6) -> 3, as stock (ADC1 on TX1, the TX macro's SWR_MIC0; ADC2 on TX2,
			 * SWR_MIC4). Two WCD ports on one master port (<1 1 2 3>, as qcm6490-idp) get the
			 * master port's transport parameters both: with ADC1 and ADC2 on at once their
			 * channel 1 samples collide.
			 */
			qcom,tx-port-mapping = <1 2 3 3>;
		};
	};

	lpass_tlmm: pinctrl@a7c0000 {
		compatible = "qcom,sm6115-lpass-lpi-pinctrl";
		reg = <0x0 0x0a7c0000 0x0 0x20000>,
		      <0x0 0x0a950000 0x0 0x10000>;

		clocks = <&q6afecc LPASS_HW_DCODEC_VOTE LPASS_CLK_ATTRIBUTE_COUPLE_NO>;
		clock-names = "audio";

		gpio-controller;
		#gpio-cells = <2>;
		gpio-ranges = <&lpass_tlmm 0 0 19>;

		/* downstream tx_swr_clk/data0/data1_active (the third data pin, LPI 18 func2, is unused) */
		lpass_tx_swr_active: tx-swr-active-state {
			clk-pins {
				pins = "gpio0";
				function = "swr_tx_clk";
				drive-strength = <10>;
				slew-rate = <1>;
				bias-disable;
			};

			data-pins {
				pins = "gpio1", "gpio2";
				function = "swr_tx_data";
				drive-strength = <10>;
				slew-rate = <1>;
				bias-bus-hold;
			};
		};

		lpass_rx_swr_active: rx-swr-active-state {
			clk-pins {
				pins = "gpio3";
				function = "swr_rx_clk";
				drive-strength = <10>;
				slew-rate = <1>;
				bias-disable;
			};

			data-pins {
				pins = "gpio4", "gpio5";
				function = "swr_rx_data";
				drive-strength = <10>;
				slew-rate = <1>;
				bias-bus-hold;
			};
		};
	};

	lpasscc: clock-controller@a7ec000 {
		compatible = "qcom,sm6115-lpasscc";
		reg = <0x0 0x0a7ec000 0x0 0x1000>;
		#reset-cells = <1>;
	};

	/*
	 * camera I2C (CCI), as downstream qcom,cci0/1: cci0's masters 0 (GPIO39/40, the main camera,
	 * its EEPROM and AF) and 1 (GPIO41/42, sensor 3); cci1's master 0 (GPIO43/44, sensors 1 and 2)
	 */
	cci0: cci@5c1b000 {
		compatible = "qcom,sm6375-cci", "qcom,msm8996-cci";
		reg = <0x0 0x05c1b000 0x0 0x1000>;
		interrupts = <GIC_SPI 206 IRQ_TYPE_EDGE_RISING>;
		clocks = <&gcc GCC_CAMSS_TOP_AHB_CLK>, <&gcc GCC_CAMSS_CCI_0_CLK>;
		clock-names = "ahb", "cci";
		assigned-clocks = <&gcc GCC_CAMSS_CCI_0_CLK>;
		assigned-clock-rates = <37500000>;
		power-domains = <&gcc CAMSS_TOP_GDSC>;
		pinctrl-0 = <&cci0_default &cci1_default>;
		pinctrl-names = "default";
		#address-cells = <1>;
		#size-cells = <0>;

		cci0_i2c0: i2c-bus@0 {
			reg = <0>;
			clock-frequency = <400000>;
			#address-cells = <1>;
			#size-cells = <0>;
		};

		cci0_i2c1: i2c-bus@1 {
			reg = <1>;
			clock-frequency = <400000>;
			#address-cells = <1>;
			#size-cells = <0>;
		};
	};

	cci1: cci@5c1c000 {
		compatible = "qcom,sm6375-cci", "qcom,msm8996-cci";
		reg = <0x0 0x05c1c000 0x0 0x1000>;
		interrupts = <GIC_SPI 214 IRQ_TYPE_EDGE_RISING>;
		clocks = <&gcc GCC_CAMSS_TOP_AHB_CLK>, <&gcc GCC_CAMSS_CCI_1_CLK>;
		clock-names = "ahb", "cci";
		assigned-clocks = <&gcc GCC_CAMSS_CCI_1_CLK>;
		assigned-clock-rates = <37500000>;
		power-domains = <&gcc CAMSS_TOP_GDSC>;
		pinctrl-0 = <&cci2_default>;
		pinctrl-names = "default";
		#address-cells = <1>;
		#size-cells = <0>;

		cci1_i2c0: i2c-bus@0 {
			reg = <0>;
			clock-frequency = <400000>;
			#address-cells = <1>;
			#size-cells = <0>;

			/*
			 * the front camera, OmniVision OV08D10 (chip id 0x5608): downstream sensor 2 on
			 * CSIPHY3, MCLK3 at 24 MHz, reset GPIO37, mounted at 270 degrees. Core 1.2 V =
			 * WL2866D LDO2, analog 2.8 V = LDO4 (each one found by switching them in turn).
			 */
			front_cam: camera@10 {
				compatible = "ovti,ov08d10";
				reg = <0x10>;
				clocks = <&gcc GCC_CAMSS_MCLK3_CLK>;
				assigned-clocks = <&gcc GCC_CAMSS_MCLK3_CLK>;
				assigned-clock-rates = <24000000>;
				reset-gpios = <&tlmm 37 GPIO_ACTIVE_LOW>;
				dovdd-supply = <&cam_vio>;
				avdd-supply = <&cam_avdd2>;
				dvdd-supply = <&cam_dvdd2>;
				pinctrl-0 = <&cam_mclk3_default &cam_reset3_default>;
				pinctrl-names = "default";
				orientation = <0>;
				rotation = <270>;

				port {
					front_cam_ep: endpoint {
						data-lanes = <1 2>;
						link-frequencies = /bits/ 64 <720000000 360000000>;
						remote-endpoint = <&camss_csiphy3_ep>;
					};
				};
			};
		};
	};

	/*
	 * CAMSS as downstream's blair DT: TFE530/CSID530 x3 (each CSID at the start of its TFE's
	 * block, the TFE core 0x1000 above it), CSIPHY 1.2.1 x4 at 0x2000 steps (kernel/patches/0018).
	 * TFE stream 0x800; CSIPHY supplies 0.88 V PM6125 L7 and 1.2 V L4. No interconnect driver:
	 * the AXI and AHB rates are set here instead.
	 */
	camss: camss@5c11000 {
		compatible = "qcom,sm6375-camss";
		reg = <0x0 0x05c11000 0x0 0x1000>,
		      <0x0 0x05c6e000 0x0 0x1000>,
		      <0x0 0x05c75000 0x0 0x1000>,
		      <0x0 0x05c7c000 0x0 0x1000>,
		      <0x0 0x05c52000 0x0 0x2000>,
		      <0x0 0x05c54000 0x0 0x2000>,
		      <0x0 0x05c56000 0x0 0x2000>,
		      <0x0 0x05c58000 0x0 0x2000>,
		      <0x0 0x05c6f000 0x0 0x4000>,
		      <0x0 0x05c76000 0x0 0x4000>,
		      <0x0 0x05c7d000 0x0 0x4000>;
		reg-names = "top",
			    "csid0", "csid1", "csid2",
			    "csiphy0", "csiphy1", "csiphy2", "csiphy3",
			    "vfe0", "vfe1", "vfe2";

		clocks = <&gcc GCC_CAMERA_AHB_CLK>,
			 <&gcc GCC_CAMSS_AXI_CLK>,
			 <&gcc GCC_CAMSS_NRT_AXI_CLK>,
			 <&gcc GCC_CAMSS_RT_AXI_CLK>,
			 <&gcc GCC_CAMSS_TFE_0_CSID_CLK>,
			 <&gcc GCC_CAMSS_TFE_1_CSID_CLK>,
			 <&gcc GCC_CAMSS_TFE_2_CSID_CLK>,
			 <&gcc GCC_CAMSS_CPHY_0_CLK>,
			 <&gcc GCC_CAMSS_CSI0PHYTIMER_CLK>,
			 <&gcc GCC_CAMSS_CPHY_1_CLK>,
			 <&gcc GCC_CAMSS_CSI1PHYTIMER_CLK>,
			 <&gcc GCC_CAMSS_CPHY_2_CLK>,
			 <&gcc GCC_CAMSS_CSI2PHYTIMER_CLK>,
			 <&gcc GCC_CAMSS_CPHY_3_CLK>,
			 <&gcc GCC_CAMSS_CSI3PHYTIMER_CLK>,
			 <&gcc GCC_CAMSS_TOP_AHB_CLK>,
			 <&gcc GCC_CAMSS_TFE_0_CLK>,
			 <&gcc GCC_CAMSS_TFE_0_CPHY_RX_CLK>,
			 <&gcc GCC_CAMSS_TFE_1_CLK>,
			 <&gcc GCC_CAMSS_TFE_1_CPHY_RX_CLK>,
			 <&gcc GCC_CAMSS_TFE_2_CLK>,
			 <&gcc GCC_CAMSS_TFE_2_CPHY_RX_CLK>;
		clock-names = "ahb",
			      "axi",
			      "camnoc_nrt_axi",
			      "camnoc_rt_axi",
			      "csi0", "csi1", "csi2",
			      "csiphy0", "csiphy0_timer",
			      "csiphy1", "csiphy1_timer",
			      "csiphy2", "csiphy2_timer",
			      "csiphy3", "csiphy3_timer",
			      "top_ahb",
			      "vfe0", "vfe0_cphy_rx",
			      "vfe1", "vfe1_cphy_rx",
			      "vfe2", "vfe2_cphy_rx";
		assigned-clocks = <&gcc GCC_CAMSS_AXI_CLK>, <&gcc GCC_CAMSS_TOP_AHB_CLK>;
		assigned-clock-rates = <300000000>, <80000000>;

		interrupts = <GIC_SPI 210 IRQ_TYPE_EDGE_RISING>,
			     <GIC_SPI 212 IRQ_TYPE_EDGE_RISING>,
			     <GIC_SPI 77 IRQ_TYPE_EDGE_RISING>,
			     <GIC_SPI 72 IRQ_TYPE_EDGE_RISING>,
			     <GIC_SPI 73 IRQ_TYPE_EDGE_RISING>,
			     <GIC_SPI 74 IRQ_TYPE_EDGE_RISING>,
			     <GIC_SPI 312 IRQ_TYPE_EDGE_RISING>,
			     <GIC_SPI 211 IRQ_TYPE_EDGE_RISING>,
			     <GIC_SPI 213 IRQ_TYPE_EDGE_RISING>,
			     <GIC_SPI 78 IRQ_TYPE_EDGE_RISING>;
		interrupt-names = "csid0", "csid1", "csid2",
				  "csiphy0", "csiphy1", "csiphy2", "csiphy3",
				  "vfe0", "vfe1", "vfe2";

		iommus = <&apps_smmu 0x800 0x0>;
		power-domains = <&gcc CAMSS_TOP_GDSC>;

		vdd-csiphy-0p9-supply = <&pm6125_l7>;
		vdd-csiphy-1p2-supply = <&pm6125_l4>;

		ports {
			#address-cells = <1>;
			#size-cells = <0>;

			port@3 {
				reg = <3>;

				camss_csiphy3_ep: endpoint {
					data-lanes = <0 1>;
					remote-endpoint = <&front_cam_ep>;
				};
			};
		};
	};
};

/*
 * ADSP (audio and the sensors): firmware from the phone's modem_a (adsp.mdt/.bNN), the carve-out
 * at 0x86700000 above. Audio runs on APR (downstream qcom,msm-audio-apr, q6core/afe/asm/adm), laid
 * out as on sm6115; the ASM's buffers go through apps SMMU stream 0xa1 (downstream msm-audio-ion).
 */
&remoteproc_adsp {
	firmware-name = "qcom/sm4375/xiaomi/sunstone/adsp.mdt";
	status = "okay";

	glink-edge {
		apr {
			compatible = "qcom,apr-v2";
			qcom,glink-channels = "apr_audio_svc";
			qcom,domain = <APR_DOMAIN_ADSP>;
			#address-cells = <1>;
			#size-cells = <0>;

			service@3 {
				reg = <APR_SVC_ADSP_CORE>;
				compatible = "qcom,q6core";
				qcom,protection-domain = "avs/audio", "msm/adsp/audio_pd";
			};

			q6afe: service@4 {
				compatible = "qcom,q6afe";
				reg = <APR_SVC_AFE>;
				qcom,protection-domain = "avs/audio", "msm/adsp/audio_pd";

				q6afedai: dais {
					compatible = "qcom,q6afe-dais";
					#address-cells = <1>;
					#size-cells = <0>;
					#sound-dai-cells = <1>;
				};

				q6afecc: clock-controller {
					compatible = "qcom,q6afe-clocks";
					#clock-cells = <2>;
				};
			};

			q6asm: service@7 {
				compatible = "qcom,q6asm";
				reg = <APR_SVC_ASM>;
				qcom,protection-domain = "avs/audio", "msm/adsp/audio_pd";

				q6asmdai: dais {
					compatible = "qcom,q6asm-dais";
					#address-cells = <1>;
					#size-cells = <0>;
					#sound-dai-cells = <1>;
					iommus = <&apps_smmu 0xa1 0x0>;

					dai@0 {
						reg = <MSM_FRONTEND_DAI_MULTIMEDIA1>;
					};

					dai@1 {
						reg = <MSM_FRONTEND_DAI_MULTIMEDIA2>;
					};

					dai@2 {
						reg = <MSM_FRONTEND_DAI_MULTIMEDIA3>;
					};
				};
			};

			q6adm: service@8 {
				compatible = "qcom,q6adm";
				reg = <APR_SVC_ADM>;
				qcom,protection-domain = "avs/audio", "msm/adsp/audio_pd";

				q6routing: routing {
					compatible = "qcom,q6adm-routing";
					#sound-dai-cells = <0>;
				};
			};
		};

		/*
		 * FastRPC to the ADSP: hexagonrpcd serves the sensors PD its registry and configs over it.
		 * Context banks: downstream msm_fastrpc_compute_cb10..14 (adsprpc-smd), streams 0xa3-0xa7.
		 */
		fastrpc {
			compatible = "qcom,fastrpc";
			qcom,glink-channels = "fastrpcglink-apps-dsp";
			label = "adsp";
			qcom,non-secure-domain;
			#address-cells = <1>;
			#size-cells = <0>;

			compute-cb@3 {
				compatible = "qcom,fastrpc-compute-cb";
				reg = <3>;
				iommus = <&apps_smmu 0xa3 0x0>;
			};

			compute-cb@4 {
				compatible = "qcom,fastrpc-compute-cb";
				reg = <4>;
				iommus = <&apps_smmu 0xa4 0x0>;
			};

			compute-cb@5 {
				compatible = "qcom,fastrpc-compute-cb";
				reg = <5>;
				iommus = <&apps_smmu 0xa5 0x0>;
			};

			compute-cb@6 {
				compatible = "qcom,fastrpc-compute-cb";
				reg = <6>;
				iommus = <&apps_smmu 0xa6 0x0>;
			};

			compute-cb@7 {
				compatible = "qcom,fastrpc-compute-cb";
				reg = <7>;
				iommus = <&apps_smmu 0xa7 0x0>;
			};
		};
	};
};

&remoteproc_mss {
	firmware-name = "qcom/sm4375/xiaomi/sunstone/modem.mdt";
	status = "okay";
};

&rpm_requests {
	regulators-0 {
		compatible = "qcom,rpm-pm6125-regulators";

		/* WLAN 1.3 V RFA, Bluetooth vddrf */
		pm6125_l2: l2 {
			regulator-min-microvolt = <1304000>;
			regulator-max-microvolt = <1304000>;
		};

		/* UFS PHY PLL (downstream 1.1-1.3 V), DSI vdda */
		pm6125_l4: l4 {
			regulator-min-microvolt = <1200000>;
			regulator-max-microvolt = <1200000>;
			regulator-allow-set-load;
		};

		/* USB HS PHY core (downstream qcom,vdd-voltage-level 0.88 V), UFS PHY */
		pm6125_l7: l7 {
			regulator-min-microvolt = <880000>;
			regulator-max-microvolt = <880000>;
			regulator-allow-set-load;
		};

		/* USB HS PHY 1.8 V */
		pm6125_l10: l10 {
			regulator-min-microvolt = <1800000>;
			regulator-max-microvolt = <1800000>;
		};

		/* Bluetooth vddio (downstream 1.7-1.9 V; the rail allows 1.504-2.0 V) */
		pm6125_l9: l9 {
			regulator-min-microvolt = <1800000>;
			regulator-max-microvolt = <1800000>;
		};

		/* UFS vccq2 */
		pm6125_l11: l11 {
			regulator-min-microvolt = <1800000>;
			regulator-max-microvolt = <1800000>;
			regulator-allow-set-load;
		};

		/* panel vddio (downstream supply entry 1.86 V) */
		pm6125_l13: l13 {
			regulator-min-microvolt = <1856000>;
			regulator-max-microvolt = <1856000>;
			regulator-allow-set-load;
		};

		/* WCD9370 buck (downstream cdc-vdd-buck 1.8 V) */
		pm6125_l14: l14 {
			regulator-min-microvolt = <1800000>;
			regulator-max-microvolt = <1800000>;
		};

		/* WLAN 1.8 V XO, Bluetooth vddxo */
		pm6125_l16: l16 {
			regulator-min-microvolt = <1800000>;
			regulator-max-microvolt = <1800000>;
		};

		/* WLAN 3.3 V ch1 */
		pm6125_l21: l21 {
			regulator-min-microvolt = <3304000>;
			regulator-max-microvolt = <3304000>;
		};

		/* WLAN 3.3 V ch0, Bluetooth vddch0 */
		pm6125_l23: l23 {
			regulator-min-microvolt = <3304000>;
			regulator-max-microvolt = <3304000>;
		};

		/* UFS vcc (downstream vcc-voltage-level 2.95-2.96 V) */
		pm6125_l24: l24 {
			regulator-min-microvolt = <2952000>;
			regulator-max-microvolt = <2952000>;
			regulator-allow-set-load;
		};
	};

	regulators-1 {
		compatible = "qcom,rpm-pmr735a-regulators";

		/* WLAN cx-mx */
		pmr735a_l2: l2 {
			regulator-min-microvolt = <640000>;
			regulator-max-microvolt = <640000>;
		};

		/* USB HS PHY 3.1 V */
		pmr735a_l7: l7 {
			regulator-min-microvolt = <3104000>;
			regulator-max-microvolt = <3104000>;
		};
	};
};

&tlmm {
	/* fingerprint SPI (qup10), owned by TZ: reading these aborts (boot-2) */
	gpio-reserved-ranges = <13 4>;

	ts_reset_default: ts-reset-default-state {
		pins = "gpio21";
		function = "gpio";
		drive-strength = <8>;
		bias-disable;
	};

	ts_int_default: ts-int-default-state {
		pins = "gpio22";
		function = "gpio";
		drive-strength = <8>;
		bias-pull-up;
	};

	mdp_vsync_default: mdp-vsync-default-state {
		pins = "gpio23";
		function = "mdp_vsync";
		drive-strength = <2>;
		bias-pull-down;
	};

	panel_avdd_default: panel-avdd-default-state {
		pins = "gpio24";
		function = "gpio";
		drive-strength = <8>;
		bias-disable;
		output-high;
	};

	qup_i2c7_default: qup-i2c7-default-state {
		pins = "gpio27", "gpio28";
		function = "qup11_f1";
		drive-strength = <2>;
		bias-pull-up;
	};

	cam_mclk0_default: cam-mclk0-default-state {
		pins = "gpio29";
		function = "cam_mclk";
		drive-strength = <2>;
		bias-disable;
	};

	cam_mclk1_default: cam-mclk1-default-state {
		pins = "gpio30";
		function = "cam_mclk";
		drive-strength = <2>;
		bias-disable;
	};

	cam_mclk2_default: cam-mclk2-default-state {
		pins = "gpio31";
		function = "cam_mclk";
		drive-strength = <2>;
		bias-disable;
	};

	cam_mclk3_default: cam-mclk3-default-state {
		pins = "gpio32";
		function = "cam_mclk";
		drive-strength = <2>;
		bias-disable;
	};

	cam_reset3_default: cam-reset3-default-state {
		pins = "gpio37";
		function = "gpio";
		drive-strength = <2>;
		bias-disable;
	};

	cam_vio_default: cam-vio-default-state {
		pins = "gpio38";
		function = "gpio";
		drive-strength = <2>;
		bias-disable;
	};

	cci0_default: cci0-default-state {
		pins = "gpio39", "gpio40";
		function = "cci_i2c";
		drive-strength = <2>;
		bias-pull-up;
	};

	cci1_default: cci1-default-state {
		pins = "gpio41", "gpio42";
		function = "cci_i2c";
		drive-strength = <2>;
		bias-pull-up;
	};

	cci2_default: cci2-default-state {
		pins = "gpio43", "gpio44";
		function = "cci_i2c";
		drive-strength = <2>;
		bias-pull-up;
	};

	chg_int_default: chg-int-default-state {
		pins = "gpio48";
		function = "gpio";
		bias-pull-up;
		input-enable;
	};

	ts_avdd_default: ts-avdd-default-state {
		pins = "gpio49";
		function = "gpio";
		drive-strength = <8>;
		output-high;
	};

	chg_en_default: chg-en-default-state {
		pins = "gpio53";
		function = "gpio";
		bias-disable;
		output-low;
	};

	qup_spi2_default: qup-spi2-default-state {
		pins = "gpio45", "gpio46", "gpio56", "gpio57";
		function = "qup02";
		drive-strength = <6>;
		bias-disable;
	};

	wcd_reset_n: wcd-reset-n-state {
		pins = "gpio83";
		function = "gpio";
		drive-strength = <16>;
		output-high;
	};

	vib_en_default: vib-en-default-state {
		pins = "gpio100";
		function = "gpio";
		drive-strength = <2>;
		bias-pull-down;
		output-low;
	};
};

/*
 * Bluetooth: the WCN3988's on the QUP0 SE1 high-speed UART (downstream qcom,msm-geni-serial-hs at
 * 0x4a84000, GPIO61-64), supplies from the downstream bt_wcn3990 node: io PM6125 L9, xtal L16,
 * core (RF) L2 and PA (ch0) L23, the last three shared with WLAN; its 0.98 V smps (PM6125 S5) has no
 * place in the binding and stays as it is. SW_CTRL on GPIO69. The firmware (apbtfw/apnv) comes from
 * the phone's bluetooth_a partition (sunstone-fw-install). No BD address is programmed: a fixed
 * locally administered one (02:53:4e:00:00:11, byte order reversed here) instead of the phone's own
 * from persist, which stays out of this repository; without one the controller stays unconfigured.
 */
/*
 * IR transmitter: an LED on the QUP0 SE2 SPI (downstream spi@4a88000, GPIO45/46/56/57, GPI DMA, the
 * SE in GSI mode), downstream ir-spi-led at 19.2 MHz; the LED is pulsed by the MOSI bit pattern.
 */
&spi2 {
	pinctrl-0 = <&qup_spi2_default>;
	pinctrl-names = "default";
	status = "okay";

	irled@0 {
		compatible = "ir-spi-led";
		reg = <0>;
		spi-max-frequency = <19200000>;
	};
};

&uart1 {
	status = "okay";

	bluetooth {
		compatible = "qcom,wcn3988-bt";
		vddio-supply = <&pm6125_l9>;
		vddxo-supply = <&pm6125_l16>;
		vddrf-supply = <&pm6125_l2>;
		vddch0-supply = <&pm6125_l23>;
		swctrl-gpios = <&tlmm 69 GPIO_ACTIVE_HIGH>;
		max-speed = <3200000>;
		local-bd-address = [11 00 00 4e 53 02];
	};
};

&usb_1 {
	status = "okay";
};

&usb_1_dwc3 {
	dr_mode = "peripheral";
};

&usb_1_hsphy {
	vdda-pll-supply = <&pm6125_l7>;
	vdda18-supply = <&pm6125_l10>;
	vdda33-supply = <&pmr735a_l7>;
	status = "okay";
};

&wifi {
	vdd-0.8-cx-mx-supply = <&pmr735a_l2>;
	vdd-1.8-xo-supply = <&pm6125_l16>;
	vdd-1.3-rfa-supply = <&pm6125_l2>;
	vdd-3.3-ch0-supply = <&pm6125_l23>;
	vdd-3.3-ch1-supply = <&pm6125_l21>;
	/*
	 * The firmware reports 00:00:.. and ath10k would pick a random address every boot (new
	 * DHCP lease each time). A fixed locally administered address instead of the phone's own
	 * MAC from persist, which stays out of this repository.
	 */
	local-mac-address = [02 53 4e 00 00 10];
	/*
	 * The board ID in OTP is unset (0xff), which matches only linux-firmware's generic entry. With
	 * the variant, ath10k first looks for "...,qmi-chip-id=150,variant=xiaomi_sunstone" in
	 * board-2.bin: an entry made from the phone's own bdwlan file (sunstone-fw-install, into
	 * /lib/firmware/updates), the generic entry as the fallback.
	 */
	qcom,calibration-variant = "xiaomi_sunstone";
	status = "okay";
};

/* the board XO frequency, left to the board by sm6375.dtsi: without it every clock rate read 0 */
&xo_board_clk {
	clock-frequency = <19200000>;
};

/*
 * Cooling maps: sm6375.dtsi has the tsens zones and their trips but binds no cooling device, so the
 * 90/95 C passive trips did nothing and only the 110 C critical trip (shutdown) acted. From the
 * first passive trip on, step_wise lowers the A55 policy (cpu0), the A78 policy (cpu6) or the GPU,
 * re-evaluating every 250 ms while above it (the zones have no polling at all otherwise, so a
 * trip crossing gave a single step), as sm6115 and sm8250 do.
 * cpu-unk0/1 (tsens 11, 12) stay unbound: which cores they watch is unknown.
 */

&{/thermal-zones/cpu0-thermal} {
	polling-delay-passive = <250>;

	cooling-maps {
		map0 {
			trip = <&cpu0_alert0>;
			cooling-device = <&cpu0 THERMAL_NO_LIMIT THERMAL_NO_LIMIT>;
		};
	};
};

&{/thermal-zones/cpu1-thermal} {
	polling-delay-passive = <250>;

	cooling-maps {
		map0 {
			trip = <&cpu1_alert0>;
			cooling-device = <&cpu0 THERMAL_NO_LIMIT THERMAL_NO_LIMIT>;
		};
	};
};

&{/thermal-zones/cpu2-thermal} {
	polling-delay-passive = <250>;

	cooling-maps {
		map0 {
			trip = <&cpu2_alert0>;
			cooling-device = <&cpu0 THERMAL_NO_LIMIT THERMAL_NO_LIMIT>;
		};
	};
};

&{/thermal-zones/cpu3-thermal} {
	polling-delay-passive = <250>;

	cooling-maps {
		map0 {
			trip = <&cpu3_alert0>;
			cooling-device = <&cpu0 THERMAL_NO_LIMIT THERMAL_NO_LIMIT>;
		};
	};
};

&{/thermal-zones/cpu4-thermal} {
	polling-delay-passive = <250>;

	cooling-maps {
		map0 {
			trip = <&cpu4_alert0>;
			cooling-device = <&cpu0 THERMAL_NO_LIMIT THERMAL_NO_LIMIT>;
		};
	};
};

&{/thermal-zones/cpu5-thermal} {
	polling-delay-passive = <250>;

	cooling-maps {
		map0 {
			trip = <&cpu5_alert0>;
			cooling-device = <&cpu0 THERMAL_NO_LIMIT THERMAL_NO_LIMIT>;
		};
	};
};

&{/thermal-zones/cluster0-thermal} {
	polling-delay-passive = <250>;

	cooling-maps {
		map0 {
			trip = <&cluster0_alert0>;
			cooling-device = <&cpu0 THERMAL_NO_LIMIT THERMAL_NO_LIMIT>;
		};
	};
};

&{/thermal-zones/cpu6-thermal} {
	polling-delay-passive = <250>;

	cooling-maps {
		map0 {
			trip = <&cpu6_alert0>;
			cooling-device = <&cpu6 THERMAL_NO_LIMIT THERMAL_NO_LIMIT>;
		};
	};
};

&{/thermal-zones/cpu7-thermal} {
	polling-delay-passive = <250>;

	cooling-maps {
		map0 {
			trip = <&cpu7_alert0>;
			cooling-device = <&cpu6 THERMAL_NO_LIMIT THERMAL_NO_LIMIT>;
		};
	};
};

&{/thermal-zones/cluster1-thermal} {
	polling-delay-passive = <250>;

	cooling-maps {
		map0 {
			trip = <&cluster1_alert0>;
			cooling-device = <&cpu6 THERMAL_NO_LIMIT THERMAL_NO_LIMIT>;
		};
	};
};

&{/thermal-zones/gpuss0-thermal} {
	polling-delay-passive = <250>;

	cooling-maps {
		map0 {
			trip = <&gpuss0_alert0>;
			cooling-device = <&gpu THERMAL_NO_LIMIT THERMAL_NO_LIMIT>;
		};
	};
};

&{/thermal-zones/gpuss1-thermal} {
	polling-delay-passive = <250>;

	cooling-maps {
		map0 {
			trip = <&gpuss1_alert0>;
			cooling-device = <&gpu THERMAL_NO_LIMIT THERMAL_NO_LIMIT>;
		};
	};
};
